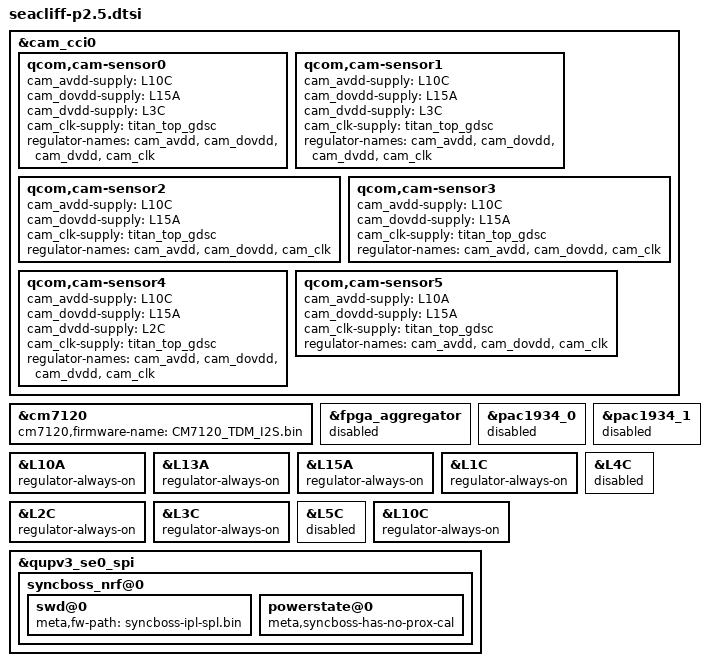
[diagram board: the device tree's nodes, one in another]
// SPDX-License-Identifier: GPL-2.0

#include "seacliff.dtsi"
#include "seacliff-adc-imu.dtsi"

&cam_cci0 {
	qcom,cam-sensor0 {
		/* T97436334: Regulators are intentionally misnamed */
		cam_avdd-supply = <&L10C>;
		cam_dovdd-supply = <&L15A>;
		cam_dvdd-supply = <&L3C>;
		cam_clk-supply = <&titan_top_gdsc>;
		regulator-names = "cam_avdd", "cam_dovdd", "cam_dvdd",
			"cam_clk";
	};

	qcom,cam-sensor1 {
		/* T97436334: Regulators are intentionally misnamed */
		cam_avdd-supply = <&L10C>;
		cam_dovdd-supply = <&L15A>;
		cam_dvdd-supply = <&L3C>;
		cam_clk-supply = <&titan_top_gdsc>;
		regulator-names = "cam_avdd", "cam_dovdd", "cam_dvdd",
			"cam_clk";
	};

	qcom,cam-sensor2 {
		/* T97436334: Regulators are intentionally misnamed */
		cam_avdd-supply = <&L10C>;
		cam_dovdd-supply = <&L15A>;
		cam_clk-supply = <&titan_top_gdsc>;
		regulator-names = "cam_avdd", "cam_dovdd",
			"cam_clk";
	};

	qcom,cam-sensor3 {
		/* T97436334: Regulators are intentionally misnamed */
		cam_avdd-supply = <&L10C>;
		cam_dovdd-supply = <&L15A>;
		cam_clk-supply = <&titan_top_gdsc>;
		regulator-names = "cam_avdd", "cam_dovdd",
			"cam_clk";
	};

	qcom,cam-sensor4 {
		/* T97436334: Regulators are intentionally misnamed */
		cam_avdd-supply = <&L10C>;
		cam_dovdd-supply = <&L15A>;
		cam_dvdd-supply = <&L2C>;
		cam_clk-supply = <&titan_top_gdsc>;
		regulator-names = "cam_avdd", "cam_dovdd", "cam_dvdd",
			"cam_clk";
	};

	qcom,cam-sensor5 {
		/* T97436334: Regulators are intentionally misnamed */
		cam_avdd-supply = <&L10A>;
		cam_dovdd-supply = <&L15A>;
		cam_clk-supply = <&titan_top_gdsc>;
		regulator-names = "cam_avdd", "cam_dovdd", "cam_clk";
	};
};

&cm7120 {
	cm7120,firmware-name = "CM7120_TDM_I2S.bin";
};

&fpga_aggregator {
	status = "disabled";
};

&pac1934_0 {
	status = "disabled";
};

&pac1934_1 {
	status = "disabled";
};

&L10A {
	/* Esker power */
	regulator-always-on;
};

&L13A {
	/* FPGA power */
	regulator-always-on;
};

&L15A {
	/* Canyon, Glacier, Teton, Esker power */
	regulator-always-on;
};

&L1C {
	/* IPD 1.8 */
	regulator-always-on;
};

&L2C {
	/* Teton power */
	regulator-always-on;
};

&L3C {
	/* Glacier power, FPGA power */
	regulator-always-on;
};

&L4C {
	status = "disabled";
};

&L5C {
	status = "disabled";
};

&L10C {
	/* Canyon, Glacier, Teton power */
	regulator-always-on;
};

&qupv3_se0_spi {
	syncboss_nrf@0 {
		swd@0 {
			meta,fw-path = "syncboss-ipl-spl.bin";
		};

		powerstate@0 {
			meta,syncboss-has-no-prox-cal;
		};
	};
};
